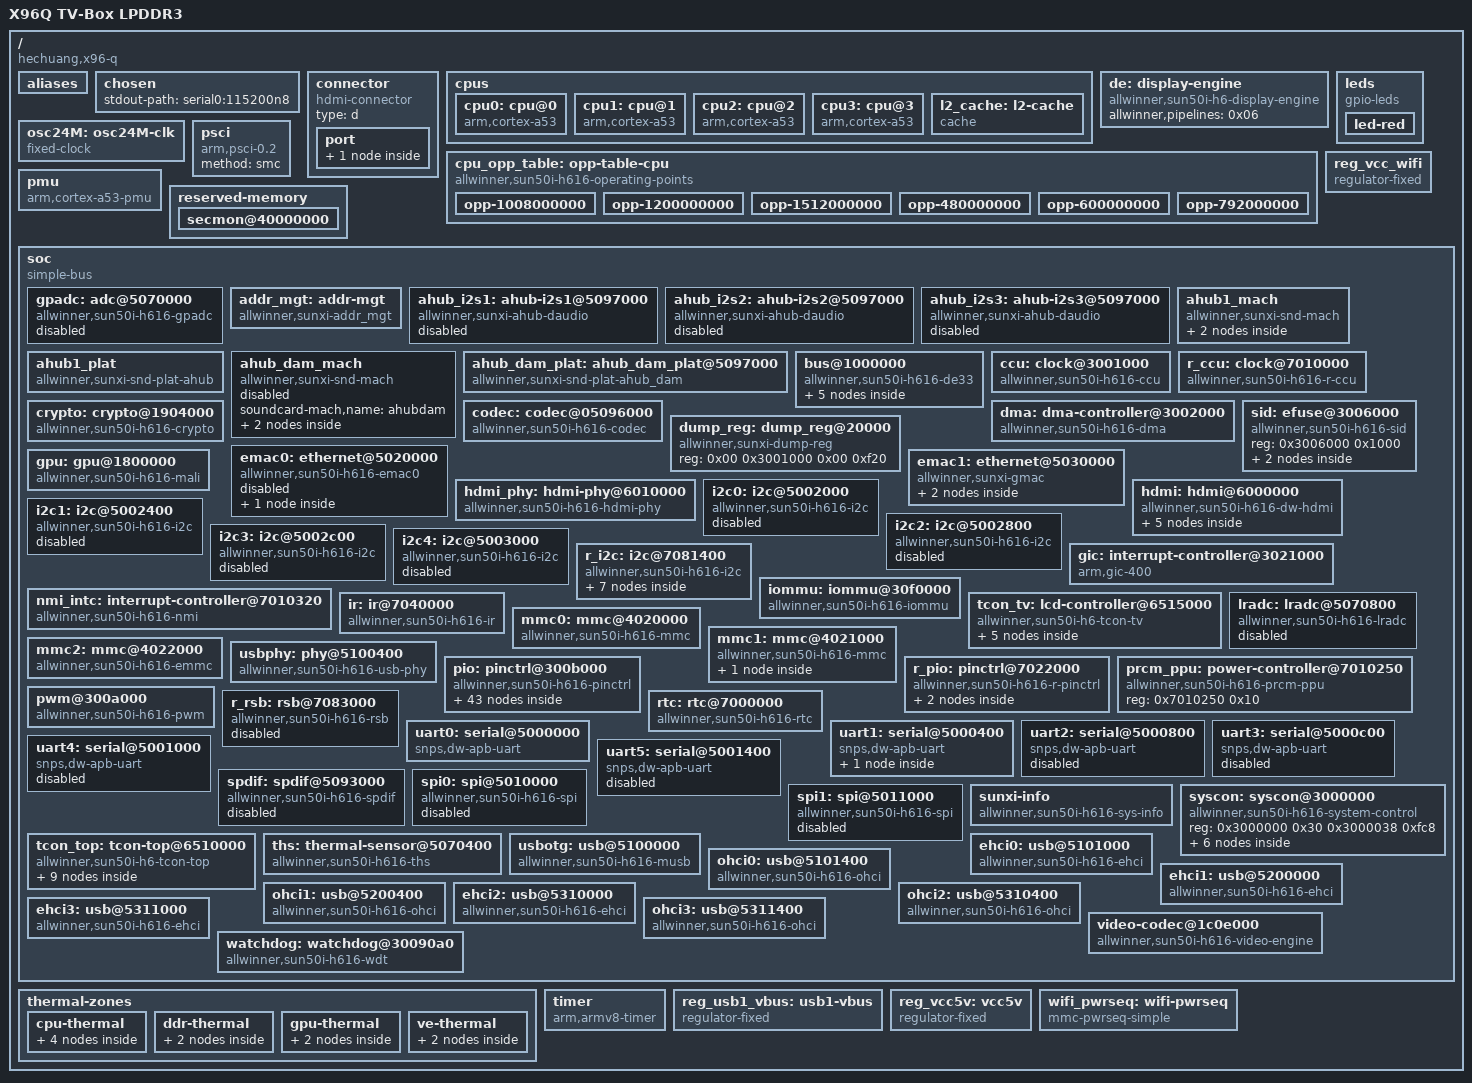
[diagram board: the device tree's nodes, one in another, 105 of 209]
/dts-v1/;

/ {
	#address-cells = <0x02>;
	#size-cells = <0x02>;
	compatible = "hechuang,x96-q", "allwinner,sun50i-h616";
	interrupt-parent = <0x01>;
	model = "X96Q TV-Box LPDDR3";

	__symbols__ {
		addr_mgt = "/soc/addr-mgt";
		ahub1_codec = "/soc/ahub1_mach/soundcard-mach,codec";
		ahub1_cpu = "/soc/ahub1_mach/soundcard-mach,cpu";
		ahub1_mach = "/soc/ahub1_mach";
		ahub1_plat = "/soc/ahub1_plat";
		ahub_dam_mach = "/soc/ahub_dam_mach";
		ahub_dam_plat = "/soc/ahub_dam_plat@5097000";
		ahub_i2s1 = "/soc/ahub-i2s1@5097000";
		ahub_i2s2 = "/soc/ahub-i2s2@5097000";
		ahub_i2s3 = "/soc/ahub-i2s3@5097000";
		axp313a = "/soc/i2c@7081400/pmic@36";
		ccu = "/soc/clock@3001000";
		codec = "/soc/codec@05096000";
		cpu0 = "/cpus/cpu@0";
		cpu1 = "/cpus/cpu@1";
		cpu2 = "/cpus/cpu@2";
		cpu3 = "/cpus/cpu@3";
		cpu_critical = "/thermal-zones/cpu-thermal/trips/cpu-trip-2";
		cpu_opp_table = "/opp-table-cpu";
		cpu_speed_grade = "/soc/efuse@3006000/cpu-speed-grade@0";
		cpu_target = "/thermal-zones/cpu-thermal/trips/cpu-trip-1";
		cpu_threshold = "/thermal-zones/cpu-thermal/trips/cpu-trip-0";
		crypto = "/soc/crypto@1904000";
		ddr_temp_critical = "/thermal-zones/ddr-thermal/trips/ddr-trip-0";
		de = "/display-engine";
		de3_sram = "/soc/syscon@3000000/sram@28000/sram-section@0";
		display_clocks = "/soc/bus@1000000/clock@8000";
		dma = "/soc/dma-controller@3002000";
		dump_reg = "/soc/dump_reg@20000";
		ehci0 = "/soc/usb@5101000";
		ehci1 = "/soc/usb@5200000";
		ehci2 = "/soc/usb@5310000";
		ehci3 = "/soc/usb@5311000";
		emac0 = "/soc/ethernet@5020000";
		emac1 = "/soc/ethernet@5030000";
		ext_rgmii_pins = "/soc/pinctrl@300b000/rgmii-pins";
		gic = "/soc/interrupt-controller@3021000";
		gpadc = "/soc/adc@5070000";
		gpu = "/soc/gpu@1800000";
		gpu_temp_critical = "/thermal-zones/gpu-thermal/trips/gpu-trip-0";
		hdmi = "/soc/hdmi@6000000";
		hdmi_con_in = "/connector/port/endpoint";
		hdmi_in = "/soc/hdmi@6000000/ports/port@0";
		hdmi_in_tcon_top = "/soc/hdmi@6000000/ports/port@0/endpoint";
		hdmi_out = "/soc/hdmi@6000000/ports/port@1";
		hdmi_out_con = "/soc/hdmi@6000000/ports/port@1/endpoint";
		hdmi_phy = "/soc/hdmi-phy@6010000";
		i2c0 = "/soc/i2c@5002000";
		i2c0_pins = "/soc/pinctrl@300b000/i2c0-pins";
		i2c1 = "/soc/i2c@5002400";
		i2c1_pi_pins = "/soc/pinctrl@300b000/i2c1-pi-pins";
		i2c2 = "/soc/i2c@5002800";
		i2c2_ph_pins = "/soc/pinctrl@300b000/i2c2-ph-pins";
		i2c2_pi_pins = "/soc/pinctrl@300b000/i2c2-pi-pins";
		i2c3 = "/soc/i2c@5002c00";
		i2c3_pa_pins = "/soc/pinctrl@300b000/i2c3-pa-pins";
		i2c3_pg_pins = "/soc/pinctrl@300b000/i2c3-pg-pins";
		i2c3_ph_pins = "/soc/pinctrl@300b000/i2c3-ph-pins";
		i2c4 = "/soc/i2c@5003000";
		i2c4_pg_pins = "/soc/pinctrl@300b000/i2c4-pg-pins";
		i2c4_ph_pins = "/soc/pinctrl@300b000/i2c4-ph-pins";
		i2s2_pins = "/soc/pinctrl@300b000/i2s2-pins";
		i2s3_pins = "/soc/pinctrl@300b000/i2s3-pins";
		iommu = "/soc/iommu@30f0000";
		ir = "/soc/ir@7040000";
		ir_rx_pin = "/soc/pinctrl@300b000/ir-rx-pin";
		l2_cache = "/cpus/l2-cache";
		lradc = "/soc/lradc@5070800";
		mdio0 = "/soc/ethernet@5020000/mdio";
		mdio1 = "/soc/ethernet@5030000/mdio";
		mixer0 = "/soc/bus@1000000/mixer@100000";
		mixer0_out = "/soc/bus@1000000/mixer@100000/ports/port@1";
		mixer0_out_tcon_top_mixer0 = "/soc/bus@1000000/mixer@100000/ports/port@1/endpoint";
		mmc0 = "/soc/mmc@4020000";
		mmc0_pins = "/soc/pinctrl@300b000/mmc0-pins";
		mmc1 = "/soc/mmc@4021000";
		mmc1_pins = "/soc/pinctrl@300b000/mmc1-pins";
		mmc2 = "/soc/mmc@4022000";
		mmc2_pins = "/soc/pinctrl@300b000/mmc2-pins";
		nmi_intc = "/soc/interrupt-controller@7010320";
		ohci0 = "/soc/usb@5101400";
		ohci1 = "/soc/usb@5200400";
		ohci2 = "/soc/usb@5310400";
		ohci3 = "/soc/usb@5311400";
		osc24M = "/osc24M-clk";
		pio = "/soc/pinctrl@300b000";
		prcm_ppu = "/soc/power-controller@7010250";
		pwm1_pg_pin = "/soc/pinctrl@300b000/pwm1-pg-pin";
		pwm1_ph_pin = "/soc/pinctrl@300b000/pwm1-ph-pin";
		pwm1_pi_pin = "/soc/pinctrl@300b000/pwm1-pi-pin";
		pwm2_ph_pin = "/soc/pinctrl@300b000/pwm2-ph-pin";
		pwm3_ph_pin = "/soc/pinctrl@300b000/pwm3-ph-pin";
		pwm4_ph_pin = "/soc/pinctrl@300b000/pwm4-ph-pin";
		pwm5_pin = "/soc/pinctrl@300b000/pwm5-pin";
		r_ccu = "/soc/clock@7010000";
		r_i2c = "/soc/i2c@7081400";
		r_i2c_pins = "/soc/pinctrl@7022000/r-i2c-pins";
		r_pio = "/soc/pinctrl@7022000";
		r_rsb = "/soc/rsb@7083000";
		r_rsb_pins = "/soc/pinctrl@7022000/r-rsb-pins";
		reg_aldo1 = "/soc/i2c@7081400/pmic@36/regulators/aldo1";
		reg_dcdc1 = "/soc/i2c@7081400/pmic@36/regulators/dcdc1";
		reg_dcdc2 = "/soc/i2c@7081400/pmic@36/regulators/dcdc2";
		reg_dcdc3 = "/soc/i2c@7081400/pmic@36/regulators/dcdc3";
		reg_dldo1 = "/soc/i2c@7081400/pmic@36/regulators/dldo1";
		reg_usb1_vbus = "/usb1-vbus";
		reg_vcc5v = "/vcc5v";
		reg_vcc_wifi = "/reg_vcc_wifi";
		rmii_phy = "/soc/ethernet@5030000/mdio/ethernet-phy@0";
		rmii_pins = "/soc/pinctrl@300b000/rmii-pins";
		rtc = "/soc/rtc@7000000";
		scpi_sram = "/soc/syscon@3000000/sram@100000/scpi-sram@17c00";
		sid = "/soc/efuse@3006000";
		spdif = "/soc/spdif@5093000";
		spdif_tx_pin = "/soc/pinctrl@300b000/spdif-tx-pin";
		spi0 = "/soc/spi@5010000";
		spi0_cs0_pin = "/soc/pinctrl@300b000/spi0-cs0-pin";
		spi0_pins = "/soc/pinctrl@300b000/spi0-pins";
		spi1 = "/soc/spi@5011000";
		spi1_cs0_pin = "/soc/pinctrl@300b000/spi1-cs0-pin";
		spi1_cs1_pin = "/soc/pinctrl@300b000/spi1-cs1-pin";
		spi1_pins = "/soc/pinctrl@300b000/spi1-pins";
		sram_a2 = "/soc/syscon@3000000/sram@100000";
		sram_c = "/soc/syscon@3000000/sram@28000";
		sram_c1 = "/soc/syscon@3000000/sram@1a00000";
		syscon = "/soc/syscon@3000000";
		tcon_top = "/soc/tcon-top@6510000";
		tcon_top_hdmi_in = "/soc/tcon-top@6510000/ports/port@4";
		tcon_top_hdmi_in_tcon_tv = "/soc/tcon-top@6510000/ports/port@4/endpoint@0";
		tcon_top_hdmi_out = "/soc/tcon-top@6510000/ports/port@5";
		tcon_top_hdmi_out_hdmi = "/soc/tcon-top@6510000/ports/port@5/endpoint";
		tcon_top_mixer0_in = "/soc/tcon-top@6510000/ports/port@0";
		tcon_top_mixer0_in_mixer0 = "/soc/tcon-top@6510000/ports/port@0/endpoint@0";
		tcon_top_mixer0_out = "/soc/tcon-top@6510000/ports/port@1";
		tcon_top_mixer0_out_tcon_tv = "/soc/tcon-top@6510000/ports/port@1/endpoint@2";
		tcon_tv = "/soc/lcd-controller@6515000";
		tcon_tv_in = "/soc/lcd-controller@6515000/ports/port@0";
		tcon_tv_in_tcon_top_mixer0 = "/soc/lcd-controller@6515000/ports/port@0/endpoint";
		tcon_tv_out = "/soc/lcd-controller@6515000/ports/port@1";
		tcon_tv_out_tcon_top = "/soc/lcd-controller@6515000/ports/port@1/endpoint@1";
		ths = "/soc/thermal-sensor@5070400";
		ths_calibration = "/soc/efuse@3006000/thermal-sensor-calibration@14";
		uart0 = "/soc/serial@5000000";
		uart0_ph_pins = "/soc/pinctrl@300b000/uart0-ph-pins";
		uart1 = "/soc/serial@5000400";
		uart1_pins = "/soc/pinctrl@300b000/uart1-pins";
		uart1_rts_cts_pins = "/soc/pinctrl@300b000/uart1-rts-cts-pins";
		uart2 = "/soc/serial@5000800";
		uart2_pg_pins = "/soc/pinctrl@300b000/uart2-pg-pins";
		uart2_pg_rts_cts_pins = "/soc/pinctrl@300b000/uart2-pg-rts-cts-pins";
		uart2_ph_pins = "/soc/pinctrl@300b000/uart2-ph-pins";
		uart2_ph_rts_cts_pins = "/soc/pinctrl@300b000/uart2-ph-rts-cts-pins";
		uart2_pi_pins = "/soc/pinctrl@300b000/uart2-pi-pins";
		uart3 = "/soc/serial@5000c00";
		uart3_pi_pins = "/soc/pinctrl@300b000/uart3-pi-pins";
		uart4 = "/soc/serial@5001000";
		uart4_pi_pins = "/soc/pinctrl@300b000/uart4-pi-pins";
		uart4_pi_rts_cts_pins = "/soc/pinctrl@300b000/uart4-pi-rts-cts-pins";
		uart5 = "/soc/serial@5001400";
		uart5_pins = "/soc/pinctrl@300b000/uart5-pins";
		usbotg = "/soc/usb@5100000";
		usbphy = "/soc/phy@5100400";
		ve_sram = "/soc/syscon@3000000/sram@1a00000/sram-section@0";
		ve_temp_critical = "/thermal-zones/ve-thermal/trips/ve-trip-0";
		watchdog = "/soc/watchdog@30090a0";
		wifi_pwrseq = "/wifi-pwrseq";
		wlan = "/soc/mmc@4021000/wifi@1";
		x32clk_fanout_pin = "/soc/pinctrl@300b000/x32clk-fanout-pin";
	};

	aliases {
		ethernet0 = "/soc/ethernet@5030000";
		ethernet1 = "/soc/mmc@4021000/wifi@1";
		mmc0 = "/soc/mmc@4020000";
		mmc2 = "/soc/mmc@4022000";
		serial0 = "/soc/serial@5000000";
	};

	chosen {
		stdout-path = "serial0:115200n8";
	};

	connector {
		compatible = "hdmi-connector";
		type = "d";

		port {

			hdmi_con_in: endpoint {
				phandle = <0x2e>;
				remote-endpoint = <0x3d>;
			};
		};
	};

	cpus {
		#address-cells = <0x01>;
		#size-cells = <0x00>;

		cpu0: cpu@0 {
			#cooling-cells = <0x02>;
			clocks = <0x02 0x15>;
			compatible = "arm,cortex-a53";
			cpu-supply = <0x05>;
			d-cache-line-size = <0x40>;
			d-cache-sets = <0x80>;
			d-cache-size = <0x8000>;
			device_type = "cpu";
			enable-method = "psci";
			i-cache-line-size = <0x40>;
			i-cache-sets = <0x100>;
			i-cache-size = <0x8000>;
			next-level-cache = <0x03>;
			operating-points-v2 = <0x04>;
			phandle = <0x07>;
			reg = <0x00>;
			status = "okay";
		};

		cpu1: cpu@1 {
			#cooling-cells = <0x02>;
			clocks = <0x02 0x15>;
			compatible = "arm,cortex-a53";
			d-cache-line-size = <0x40>;
			d-cache-sets = <0x80>;
			d-cache-size = <0x8000>;
			device_type = "cpu";
			enable-method = "psci";
			i-cache-line-size = <0x40>;
			i-cache-sets = <0x100>;
			i-cache-size = <0x8000>;
			next-level-cache = <0x03>;
			operating-points-v2 = <0x04>;
			phandle = <0x08>;
			reg = <0x01>;
		};

		cpu2: cpu@2 {
			#cooling-cells = <0x02>;
			clocks = <0x02 0x15>;
			compatible = "arm,cortex-a53";
			d-cache-line-size = <0x40>;
			d-cache-sets = <0x80>;
			d-cache-size = <0x8000>;
			device_type = "cpu";
			enable-method = "psci";
			i-cache-line-size = <0x40>;
			i-cache-sets = <0x100>;
			i-cache-size = <0x8000>;
			next-level-cache = <0x03>;
			operating-points-v2 = <0x04>;
			phandle = <0x09>;
			reg = <0x02>;
		};

		cpu3: cpu@3 {
			#cooling-cells = <0x02>;
			clocks = <0x02 0x15>;
			compatible = "arm,cortex-a53";
			d-cache-line-size = <0x40>;
			d-cache-sets = <0x80>;
			d-cache-size = <0x8000>;
			device_type = "cpu";
			enable-method = "psci";
			i-cache-line-size = <0x40>;
			i-cache-sets = <0x100>;
			i-cache-size = <0x8000>;
			next-level-cache = <0x03>;
			operating-points-v2 = <0x04>;
			phandle = <0x0a>;
			reg = <0x03>;
		};

		l2_cache: l2-cache {
			cache-level = <0x02>;
			cache-line-size = <0x40>;
			cache-sets = <0x100>;
			cache-size = <0x40000>;
			cache-unified;
			compatible = "cache";
			phandle = <0x03>;
		};
	};

	de: display-engine {
		allwinner,pipelines = <0x06>;
		compatible = "allwinner,sun50i-h6-display-engine";
		phandle = <0x3e>;
		status = "okay";
	};

	leds {
		compatible = "gpio-leds";

		led-red {
			color = <0x01>;
			function = "disk-activity";
			gpios = <0x18 0x07 0x06 0x00>;
			linux,default-trigger = "mmc0";
		};
	};

	cpu_opp_table: opp-table-cpu {
		compatible = "allwinner,sun50i-h616-operating-points";
		nvmem-cells = <0x3c>;
		opp-shared;
		phandle = <0x04>;

		opp-1008000000 {
			clock-latency-ns = <0x3b9b0>;
			opp-hz = <0x00 0x3c14dc00>;
			opp-microvolt-speed0 = <0xe09c0 0xe09c0 0x10c8e0>;
			opp-microvolt-speed1 = <0xe09c0 0xe09c0 0x10c8e0>;
			opp-microvolt-speed2 = <0xe09c0 0xe09c0 0x10c8e0>;
		};

		opp-1200000000 {
			clock-latency-ns = <0x3b9b0>;
			opp-hz = <0x00 0x47868c00>;
			opp-microvolt-speed0 = <0xef420 0xef420 0x10c8e0>;
			opp-microvolt-speed1 = <0xef420 0xef420 0x10c8e0>;
			opp-microvolt-speed2 = <0xef420 0xef420 0x10c8e0>;
		};

		opp-1512000000 {
			clock-latency-ns = <0x3b9b0>;
			opp-hz = <0x00 0x5a1f4a00>;
			opp-microvolt-speed0 = <0x10c8e0 0x10c8e0 0x10c8e0>;
			opp-microvolt-speed1 = <0x10c8e0 0x10c8e0 0x10c8e0>;
			opp-microvolt-speed2 = <0x10c8e0 0x10c8e0 0x10c8e0>;
		};

		opp-480000000 {
			clock-latency-ns = <0x3b9b0>;
			opp-hz = <0x00 0x1c9c3800>;
			opp-microvolt-speed0 = <0xdbba0 0xdbba0 0x10c8e0>;
			opp-microvolt-speed1 = <0xdbba0 0xdbba0 0x10c8e0>;
			opp-microvolt-speed2 = <0xdbba0 0xdbba0 0x10c8e0>;
		};

		opp-600000000 {
			clock-latency-ns = <0x3b9b0>;
			opp-hz = <0x00 0x23c34600>;
			opp-microvolt-speed0 = <0xdbba0 0xdbba0 0x10c8e0>;
			opp-microvolt-speed1 = <0xdbba0 0xdbba0 0x10c8e0>;
			opp-microvolt-speed2 = <0xdbba0 0xdbba0 0x10c8e0>;
		};

		opp-792000000 {
			clock-latency-ns = <0x3b9b0>;
			opp-hz = <0x00 0x2f34f600>;
			opp-microvolt-speed0 = <0xdbba0 0xdbba0 0x10c8e0>;
			opp-microvolt-speed1 = <0xdbba0 0xdbba0 0x10c8e0>;
			opp-microvolt-speed2 = <0xdbba0 0xdbba0 0x10c8e0>;
		};
	};

	osc24M: osc24M-clk {
		#clock-cells = <0x00>;
		clock-frequency = <0x16e3600>;
		clock-output-names = "osc24M";
		compatible = "fixed-clock";
		phandle = <0x12>;
	};

	pmu {
		compatible = "arm,cortex-a53-pmu";
		interrupt-affinity = <0x07 0x08 0x09 0x0a>;
		interrupts = <0x00 0x8c 0x04 0x00 0x8d 0x04 0x00 0x8e 0x04 0x00 0x8f 0x04>;
	};

	psci {
		compatible = "arm,psci-0.2";
		method = "smc";
	};

	reg_vcc_wifi: reg_vcc_wifi {
		compatible = "regulator-fixed";
		enable-active-high;
		gpio = <0x18 0x06 0x12 0x00>;
		phandle = <0x16>;
		regulator-always-on;
		regulator-max-microvolt = <0x325aa0>;
		regulator-min-microvolt = <0x325aa0>;
		regulator-name = "vcc-wifi";
		status = "okay";
	};

	reserved-memory {
		#address-cells = <0x02>;
		#size-cells = <0x02>;
		ranges;

		secmon@40000000 {
			no-map;
			reg = <0x00 0x40000000 0x00 0x80000>;
		};
	};

	soc {
		#address-cells = <0x01>;
		#size-cells = <0x01>;
		compatible = "simple-bus";
		ranges = <0x00 0x00 0x00 0x40000000>;

		gpadc: adc@5070000 {
			#io-channel-cells = <0x01>;
			clocks = <0x02 0x81>;
			compatible = "allwinner,sun50i-h616-gpadc", "allwinner,sun20i-d1-gpadc";
			interrupts = <0x00 0x12 0x04>;
			phandle = <0x80>;
			reg = <0x5070000 0x400>;
			resets = <0x02 0x3c>;
			status = "disabled";
		};

		addr_mgt: addr-mgt {
			compatible = "allwinner,sunxi-addr_mgt";
			phandle = <0xa2>;
			status = "okay";
			type_addr_bt = <0x02>;
			type_addr_eth = <0x02>;
			type_addr_wifi = <0x02>;
		};

		ahub_i2s1: ahub-i2s1@5097000 {
			#sound-dai-cells = <0x00>;
			audio_format = <0x01>;
			clock-names = "apb", "audio-codec-1x", "audio-codec-4x", "audio-hub";
			clocks = <0x02 0x5f 0x02 0x5b 0x02 0x5c 0x02 0x5e>;
			compatible = "allwinner,sunxi-ahub-daudio";
			daudio_master = <0x04>;
			frametype = <0x00>;
			mclk_div = <0x01>;
			pcm_lrck_period = <0x20>;
			phandle = <0x86>;
			pinconfig = <0x00>;
			reg = <0x5097000 0xadf>;
			signal_inversion = <0x01>;
			slot_width_select = <0x20>;
			status = "disabled";
			tdm_config = <0x01>;
			tdm_num = <0x01>;
		};

		ahub_i2s2: ahub-i2s2@5097000 {
			audio_format = <0x01>;
			clock-names = "apb", "audio-codec-1x", "audio-codec-4x", "audio-hub";
			clocks = <0x02 0x5f 0x02 0x5b 0x02 0x5c 0x02 0x5e>;
			compatible = "allwinner,sunxi-ahub-daudio";
			daudio_master = <0x04>;
			frametype = <0x00>;
			mclk_div = <0x04>;
			pcm_lrck_period = <0x20>;
			phandle = <0x87>;
			pinconfig = <0x01>;
			reg = <0x5097000 0xadf>;
			signal_inversion = <0x01>;
			slot_width_select = <0x20>;
			status = "disabled";
			tdm_config = <0x01>;
			tdm_num = <0x02>;
		};

		ahub_i2s3: ahub-i2s3@5097000 {
			audio_format = <0x01>;
			clock-names = "apb", "audio-codec-1x", "audio-codec-4x", "audio-hub";
			clocks = <0x02 0x5f 0x02 0x5b 0x02 0x5c 0x02 0x5e>;
			compatible = "allwinner,sunxi-ahub-daudio";
			daudio_master = <0x04>;
			frametype = <0x00>;
			mclk_div = <0x04>;
			pcm_lrck_period = <0x20>;
			phandle = <0x88>;
			pinconfig = <0x01>;
			reg = <0x5097000 0xadf>;
			signal_inversion = <0x01>;
			slot_width_select = <0x20>;
			status = "disabled";
			tdm_config = <0x01>;
			tdm_num = <0x03>;
		};

		ahub1_mach: ahub1_mach {
			compatible = "allwinner,sunxi-snd-mach";
			phandle = <0x84>;
			soundcard-mach,bitclock-master = <0x27>;
			soundcard-mach,format = "i2s";
			soundcard-mach,frame-master = <0x27>;
			soundcard-mach,name = "HDMI";
			soundcard-mach,slot-num = <0x02>;
			soundcard-mach,slot-width = <0x20>;
			status = "okay";

			ahub1_codec: soundcard-mach,codec {
				phandle = <0x85>;
				sound-dai = <0x29>;
			};

			ahub1_cpu: soundcard-mach,cpu {
				phandle = <0x27>;
				sound-dai = <0x28>;
				soundcard-mach,mclk-fs = <0x00>;
				soundcard-mach,pll-fs = <0x04>;
			};
		};

		ahub1_plat: ahub1_plat {
			#sound-dai-cells = <0x00>;
			apb_num = <0x01>;
			capture_cma = <0x80>;
			compatible = "allwinner,sunxi-snd-plat-ahub";
			dma-names = "tx", "rx";
			dmas = <0x1a 0x04 0x1a 0x04>;
			phandle = <0x28>;
			playback_cma = <0x80>;
			rx_fifo_size = <0x80>;
			rx_pin = <0x00>;
			status = "okay";
			tdm_num = <0x01>;
			tx_fifo_size = <0x80>;
			tx_pin = <0x00>;
		};

		ahub_dam_mach: ahub_dam_mach {
			compatible = "allwinner,sunxi-snd-mach";
			phandle = <0x83>;
			soundcard-mach,name = "ahubdam";
			status = "disabled";

			soundcard-mach,codec {
			};

			soundcard-mach,cpu {
				sound-dai = <0x26>;
			};
		};

		ahub_dam_plat: ahub_dam_plat@5097000 {
			#sound-dai-cells = <0x00>;
			clock-names = "clk_pll_audio", "clk_pll_audio_4x", "clk_audio_hub", "clk_bus_audio_hub";
			clocks = <0x02 0x5b 0x02 0x5c 0x02 0x5e 0x02 0x5f>;
			compatible = "allwinner,sunxi-snd-plat-ahub_dam";
			phandle = <0x26>;
			reg = <0x5097000 0x1000>;
			resets = <0x02 0x25>;
			status = "okay";
		};

		bus@1000000 {
			#address-cells = <0x01>;
			#size-cells = <0x01>;
			allwinner,sram = <0x0b 0x01>;
			compatible = "allwinner,sun50i-h616-de33", "allwinner,sun50i-a64-de2";
			ranges = <0x00 0x1000000 0x400000>;
			reg = <0x1000000 0x400000>;

			display_clocks: clock@8000 {
				#clock-cells = <0x01>;
				#reset-cells = <0x01>;
				clock-names = "mod", "bus";
				clocks = <0x02 0x1d 0x02 0x1e>;
				compatible = "allwinner,sun50i-h616-de33-clk";
				phandle = <0x0c>;
				reg = <0x8000 0x100>;
				resets = <0x02 0x01>;
			};

			mixer0: mixer@100000 {
				clock-names = "bus", "mod";
				clocks = <0x0c 0x00 0x0c 0x06>;
				compatible = "allwinner,sun50i-h616-de33-mixer-0";
				phandle = <0x06>;
				reg = <0x100000 0x100000 0x8100 0x40 0x280000 0x20000>;
				resets = <0x0c 0x00>;

				ports {
					#address-cells = <0x01>;
					#size-cells = <0x00>;

					mixer0_out: port@1 {
						phandle = <0x3f>;
						reg = <0x01>;

						mixer0_out_tcon_top_mixer0: endpoint {
							phandle = <0x2f>;
							remote-endpoint = <0x0d>;
						};
					};
				};
			};
		};

		ccu: clock@3001000 {
			#clock-cells = <0x01>;
			#reset-cells = <0x01>;
			clock-names = "hosc", "losc", "iosc";
			clocks = <0x12 0x10 0x00 0x10 0x02>;
			compatible = "allwinner,sun50i-h616-ccu";
			phandle = <0x02>;
			reg = <0x3001000 0x1000>;
		};

		r_ccu: clock@7010000 {
			#clock-cells = <0x01>;
			#reset-cells = <0x01>;
			clock-names = "hosc", "losc", "iosc", "pll-periph";
			clocks = <0x12 0x10 0x00 0x10 0x02 0x02 0x04>;
			compatible = "allwinner,sun50i-h616-r-ccu";
			phandle = <0x36>;
			reg = <0x7010000 0x210>;
		};

		codec: codec@05096000 {
			#sound-dai-cells = <0x00>;
			allwinner,audio-routing = "Line Out", "LINEOUT";
			clock-names = "apb", "audio-codec-1x", "audio-codec-4x";
			clocks = <0x02 0x5d 0x02 0x5b 0x02 0x5c>;
			compatible = "allwinner,sun50i-h616-codec";
			dma-names = "tx";
			dmas = <0x1a 0x06>;
			interrupts = <0x00 0x3a 0x04>;
			phandle = <0x82>;
			reg = <0x5096000 0x31c>;
			resets = <0x02 0x24>;
			status = "okay";
		};

		crypto: crypto@1904000 {
			clock-names = "bus", "mod", "ram", "trng";
			clocks = <0x02 0x27 0x02 0x26 0x02 0x34 0x10 0x02>;
			compatible = "allwinner,sun50i-h616-crypto";
			interrupts = <0x00 0x5b 0x04>;
			phandle = <0x41>;
			reg = <0x1904000 0x800>;
			resets = <0x02 0x04>;
		};

		dma: dma-controller@3002000 {
			#dma-cells = <0x01>;
			clock-names = "bus", "mbus";
			clocks = <0x02 0x2a 0x02 0x32>;
			compatible = "allwinner,sun50i-h616-dma", "allwinner,sun50i-a100-dma";
			dma-channels = <0x10>;
			dma-requests = <0x31>;
			interrupts = <0x00 0x2a 0x04>;
			phandle = <0x1a>;
			reg = <0x3002000 0x1000>;
			resets = <0x02 0x06>;
		};

		dump_reg: dump_reg@20000 {
			compatible = "allwinner,sunxi-dump-reg";
			phandle = <0xa1>;
			reg = <0x00 0x3001000 0x00 0xf20>;
			status = "okay";
		};

		sid: efuse@3006000 {
			#address-cells = <0x01>;
			#size-cells = <0x01>;
			compatible = "allwinner,sun50i-h616-sid", "allwinner,sun50i-a64-sid";
			phandle = <0x46>;
			reg = <0x3006000 0x1000>;

			cpu_speed_grade: cpu-speed-grade@0 {
				phandle = <0x3c>;
				reg = <0x00 0x02>;
			};

			ths_calibration: thermal-sensor-calibration@14 {
				phandle = <0x25>;
				reg = <0x14 0x08>;
			};
		};

		emac0: ethernet@5020000 {
			clock-names = "stmmaceth";
			clocks = <0x02 0x52>;
			compatible = "allwinner,sun50i-h616-emac0", "allwinner,sun50i-a64-emac";
			interrupt-names = "macirq";
			interrupts = <0x00 0x0e 0x04>;
			phandle = <0x7b>;
			reg = <0x5020000 0x10000>;
			reset-names = "stmmaceth";
			resets = <0x02 0x1e>;
			status = "disabled";
			syscon = <0x20>;

			mdio0: mdio {
				#address-cells = <0x01>;
				#size-cells = <0x00>;
				compatible = "snps,dwmac-mdio";
				phandle = <0x7c>;
			};
		};

		emac1: ethernet@5030000 {
			allwinner,rx-delay-ps = <0xc1c>;
			allwinner,tx-delay-ps = <0x2bc>;
			clock-names = "bus-emac1", "emac-25m";
			clocks = <0x02 0x53 0x02 0x51>;
			compatible = "allwinner,sunxi-gmac";
			gmac-power0;
			gmac-power1;
			gmac-power2;
			interrupt-names = "gmacirq";
			interrupts = <0x00 0x0f 0x04>;
			phandle = <0x7d>;
			phy-handle = <0x22>;
			phy-mode = "rmii";
			phy-rst;
			phy-supply = <0x23>;
			pinctrl-0 = <0x21>;
			pinctrl-names = "default";
			reg = <0x5030000 0x10000 0x3000034 0x04>;
			reg-names = "gmac1_reg", "ephy_reg";
			reset-names = "stmmaceth";
			resets = <0x02 0x1f>;
			rx-delay = <0x1f>;
			status = "okay";
			tx-delay = <0x07>;

			mdio1: mdio {
				#address-cells = <0x01>;
				#size-cells = <0x00>;
				compatible = "ethernet-phy-ieee802.3-c22";
				phandle = <0x7e>;

				rmii_phy: ethernet-phy@0 {
					compatible = "ethernet-phy-ieee802.3-c22";
					phandle = <0x22>;
					reg = <0x00>;
				};
			};
		};

		gpu: gpu@1800000 {
			clock-names = "core", "bus";
			clocks = <0x02 0x23 0x02 0x24>;
			compatible = "allwinner,sun50i-h616-mali", "arm,mali-bifrost";
			interrupt-names = "job", "mmu", "gpu";
			interrupts = <0x00 0x5f 0x04 0x00 0x60 0x04 0x00 0x61 0x04>;
			mali-supply = <0x0f>;
			phandle = <0x40>;
			power-domains = <0x0e 0x02>;
			reg = <0x1800000 0x40000>;
			resets = <0x02 0x03>;
			status = "okay";
		};

		hdmi_phy: hdmi-phy@6010000 {
			#phy-cells = <0x00>;
			clock-names = "bus", "mod";
			clocks = <0x02 0x75 0x02 0x73>;
			compatible = "allwinner,sun50i-h616-hdmi-phy";
			phandle = <0x2c>;
			reg = <0x6010000 0x10000>;
			reset-names = "phy";
			resets = <0x02 0x34>;
		};

		hdmi: hdmi@6000000 {
			#sound-dai-cells = <0x00>;
			clock-names = "iahb", "isfr", "tmds", "cec", "hdcp", "hdcp-bus";
			clocks = <0x02 0x75 0x02 0x73 0x02 0x72 0x02 0x74 0x02 0x7e 0x02 0x7f>;
			compatible = "allwinner,sun50i-h616-dw-hdmi", "allwinner,sun50i-h6-dw-hdmi";
			hvcc-supply = <0x23>;
			interrupts = <0x00 0x3f 0x04>;
			phandle = <0x29>;
			phy-names = "phy";
			phys = <0x2c>;
			reg = <0x6000000 0x10000>;
			reg-io-width = <0x01>;
			reset-names = "ctrl", "hdcp";
			resets = <0x02 0x33 0x02 0x3a>;
			status = "okay";

			ports {
				#address-cells = <0x01>;
				#size-cells = <0x00>;

				hdmi_in: port@0 {
					phandle = <0x92>;
					reg = <0x00>;

					hdmi_in_tcon_top: endpoint {
						phandle = <0x32>;
						remote-endpoint = <0x2d>;
					};
				};

				hdmi_out: port@1 {
					phandle = <0x93>;
					reg = <0x01>;

					hdmi_out_con: endpoint {
						phandle = <0x3d>;
						remote-endpoint = <0x2e>;
					};
				};
			};
		};

		i2c0: i2c@5002000 {
			#address-cells = <0x01>;
			#size-cells = <0x00>;
			clocks = <0x02 0x48>;
			compatible = "allwinner,sun50i-h616-i2c", "allwinner,sun8i-v536-i2c", "allwinner,sun6i-a31-i2c";
			dma-names = "rx", "tx";
			dmas = <0x1a 0x2b 0x1a 0x2b>;
			interrupts = <0x00 0x06 0x04>;
			phandle = <0x74>;
			pinctrl-0 = <0x1f>;
			pinctrl-names = "default";
			reg = <0x5002000 0x400>;
			resets = <0x02 0x17>;
			status = "disabled";
		};

		i2c1: i2c@5002400 {
			#address-cells = <0x01>;
			#size-cells = <0x00>;
			clocks = <0x02 0x49>;
			compatible = "allwinner,sun50i-h616-i2c", "allwinner,sun8i-v536-i2c", "allwinner,sun6i-a31-i2c";
			dma-names = "rx", "tx";
			dmas = <0x1a 0x2c 0x1a 0x2c>;
			interrupts = <0x00 0x07 0x04>;
			phandle = <0x75>;
			reg = <0x5002400 0x400>;
			resets = <0x02 0x18>;
			status = "disabled";
		};

		i2c2: i2c@5002800 {
			#address-cells = <0x01>;
			#size-cells = <0x00>;
			clocks = <0x02 0x4a>;
			compatible = "allwinner,sun50i-h616-i2c", "allwinner,sun8i-v536-i2c", "allwinner,sun6i-a31-i2c";
			dma-names = "rx", "tx";
			dmas = <0x1a 0x2d 0x1a 0x2d>;
			interrupts = <0x00 0x08 0x04>;
			phandle = <0x76>;
			reg = <0x5002800 0x400>;
			resets = <0x02 0x19>;
			status = "disabled";
		};

		i2c3: i2c@5002c00 {
			#address-cells = <0x01>;
			#size-cells = <0x00>;
			clocks = <0x02 0x4b>;
			compatible = "allwinner,sun50i-h616-i2c", "allwinner,sun8i-v536-i2c", "allwinner,sun6i-a31-i2c";
			dma-names = "rx", "tx";
			dmas = <0x1a 0x2e 0x1a 0x2e>;
			interrupts = <0x00 0x09 0x04>;
			phandle = <0x77>;
			reg = <0x5002c00 0x400>;
			resets = <0x02 0x1a>;
			status = "disabled";
		};

		i2c4: i2c@5003000 {
			#address-cells = <0x01>;
			#size-cells = <0x00>;
			clocks = <0x02 0x4c>;
			compatible = "allwinner,sun50i-h616-i2c", "allwinner,sun8i-v536-i2c", "allwinner,sun6i-a31-i2c";
			dma-names = "rx", "tx";
			dmas = <0x1a 0x2f 0x1a 0x2f>;
			interrupts = <0x00 0x0a 0x04>;
			phandle = <0x78>;
			reg = <0x5003000 0x400>;
			resets = <0x02 0x1b>;
			status = "disabled";
		};

		r_i2c: i2c@7081400 {
			#address-cells = <0x01>;
			#size-cells = <0x00>;
			clocks = <0x36 0x08>;
			compatible = "allwinner,sun50i-h616-i2c", "allwinner,sun8i-v536-i2c", "allwinner,sun6i-a31-i2c";
			dma-names = "rx", "tx";
			dmas = <0x1a 0x30 0x1a 0x30>;
			interrupts = <0x00 0x69 0x04>;
			phandle = <0x9d>;
			pinctrl-0 = <0x38>;
			pinctrl-names = "default";
			reg = <0x7081400 0x400>;
			resets = <0x36 0x04>;
			status = "okay";

			axp313a: pmic@36 {
				compatible = "x-powers,axp313a";
				phandle = <0x9e>;
				reg = <0x36>;
				vin1-supply = <0x39>;
				vin2-supply = <0x39>;
				vin3-supply = <0x39>;
				wakeup-source;

				regulators {

					reg_aldo1: aldo1 {
						phandle = <0x23>;
						regulator-always-on;
						regulator-max-microvolt = <0x1b7740>;
						regulator-min-microvolt = <0x1b7740>;
						regulator-name = "vcc1v8";
					};

					reg_dcdc1: dcdc1 {
						phandle = <0x0f>;
						regulator-always-on;
						regulator-max-microvolt = <0x11b340>;
						regulator-min-microvolt = <0xc5c10>;
						regulator-name = "vdd-gpu";
					};

					reg_dcdc2: dcdc2 {
						phandle = <0x05>;
						regulator-always-on;
						regulator-max-microvolt = <0x11b340>;
						regulator-min-microvolt = <0xc5c10>;
						regulator-name = "vdd-cpu";
					};

					reg_dcdc3: dcdc3 {
						phandle = <0x9f>;
						regulator-always-on;
						regulator-max-microvolt = <0x124f80>;
						regulator-min-microvolt = <0x124f80>;
						regulator-name = "vdd-dram";
					};

					reg_dldo1: dldo1 {
						phandle = <0x14>;
						regulator-always-on;
						regulator-max-microvolt = <0x325aa0>;
						regulator-min-microvolt = <0x325aa0>;
						regulator-name = "vcc3v3";
					};
				};
			};
		};

		gic: interrupt-controller@3021000 {
			#interrupt-cells = <0x03>;
			compatible = "arm,gic-400";
			interrupt-controller;
			interrupts = <0x01 0x09 0xf04>;
			phandle = <0x01>;
			reg = <0x3021000 0x1000 0x3022000 0x2000 0x3024000 0x2000 0x3026000 0x2000>;
		};

		nmi_intc: interrupt-controller@7010320 {
			#interrupt-cells = <0x02>;
			compatible = "allwinner,sun50i-h616-nmi", "allwinner,sun9i-a80-nmi";
			interrupt-controller;
			interrupts = <0x00 0x67 0x04>;
			phandle = <0x9b>;
			reg = <0x7010320 0x0c>;
		};

		iommu: iommu@30f0000 {
			#iommu-cells = <0x01>;
			clocks = <0x02 0x30>;
			compatible = "allwinner,sun50i-h616-iommu", "allwinner,sun50i-h6-iommu";
			interrupts = <0x00 0x3d 0x04>;
			phandle = <0x69>;
			reg = <0x30f0000 0x10000>;
			resets = <0x02 0x0b>;
		};

		ir: ir@7040000 {
			clock-names = "apb", "ir";
			clocks = <0x36 0x09 0x36 0x0b>;
			compatible = "allwinner,sun50i-h616-ir", "allwinner,sun6i-a31-ir";
			interrupts = <0x00 0x6a 0x04>;
			linux,rc-map-name = "rc-beelink-gs1";
			phandle = <0x9c>;
			pinctrl-0 = <0x37>;
			pinctrl-names = "default";
			reg = <0x7040000 0x400>;
			resets = <0x36 0x05>;
			status = "okay";
		};

		tcon_tv: lcd-controller@6515000 {
			clock-names = "ahb", "tcon-ch1";
			clocks = <0x02 0x79 0x33 0x00>;
			compatible = "allwinner,sun50i-h6-tcon-tv", "allwinner,sun8i-r40-tcon-tv";
			interrupts = <0x00 0x42 0x04>;
			phandle = <0x98>;
			reg = <0x6515000 0x1000>;
			reset-names = "lcd";
			resets = <0x02 0x36>;

			ports {
				#address-cells = <0x01>;
				#size-cells = <0x00>;

				tcon_tv_in: port@0 {
					phandle = <0x99>;
					reg = <0x00>;

					tcon_tv_in_tcon_top_mixer0: endpoint {
						phandle = <0x30>;
						remote-endpoint = <0x34>;
					};
				};

				tcon_tv_out: port@1 {
					#address-cells = <0x01>;
					#size-cells = <0x00>;
					phandle = <0x9a>;
					reg = <0x01>;

					tcon_tv_out_tcon_top: endpoint@1 {
						phandle = <0x31>;
						reg = <0x01>;
						remote-endpoint = <0x35>;
					};
				};
			};
		};

		lradc: lradc@5070800 {
			clocks = <0x02 0x71>;
			compatible = "allwinner,sun50i-h616-lradc", "allwinner,sun50i-r329-lradc";
			interrupts = <0x00 0x14 0x04>;
			phandle = <0x81>;
			reg = <0x5070800 0x400>;
			resets = <0x02 0x3b>;
			status = "disabled";
		};

		mmc0: mmc@4020000 {
			#address-cells = <0x01>;
			#size-cells = <0x00>;
			broken-cd;
			bus-width = <0x04>;
			cap-mmc-highspeed;
			cap-sd-highspeed;
			cap-sdio-irq;
			clock-names = "ahb", "mmc";
			clocks = <0x02 0x3f 0x02 0x3c>;
			compatible = "allwinner,sun50i-h616-mmc", "allwinner,sun50i-a100-mmc";
			interrupts = <0x00 0x23 0x04>;
			max-frequency = <0x8f0d180>;
			mmc-ddr-3_3v;
			phandle = <0x6a>;
			pinctrl-0 = <0x13>;
			pinctrl-names = "default";
			reg = <0x4020000 0x1000>;
			reset-names = "ahb";
			resets = <0x02 0x0e>;
			status = "okay";
			vmmc-supply = <0x14>;
		};

		mmc1: mmc@4021000 {
			#address-cells = <0x01>;
			#size-cells = <0x00>;
			bus-width = <0x04>;
			cap-mmc-highspeed;
			cap-sd-highspeed;
			cap-sdio-irq;
			clock-names = "ahb", "mmc";
			clocks = <0x02 0x40 0x02 0x3d>;
			compatible = "allwinner,sun50i-h616-mmc", "allwinner,sun50i-a100-mmc";
			interrupts = <0x00 0x24 0x04>;
			max-frequency = <0x8f0d180>;
			mmc-ddr-3_3v;
			mmc-pwrseq = <0x17>;
			non-removable;
			phandle = <0x6b>;
			pinctrl-0 = <0x15>;
			pinctrl-names = "default";
			reg = <0x4021000 0x1000>;
			reset-names = "ahb";
			resets = <0x02 0x0f>;
			status = "okay";
			vmmc-supply = <0x14>;
			vqmmc-supply = <0x16>;

			wlan: wifi@1 {
				interrupt-names = "host-wake";
				interrupt-parent = <0x18>;
				interrupts = <0x06 0x0f 0x01>;
				phandle = <0x6c>;
				reg = <0x01>;
			};
		};

		mmc2: mmc@4022000 {
			#address-cells = <0x01>;
			#size-cells = <0x00>;
			bus-width = <0x08>;
			cap-mmc-highspeed;
			cap-mmc-hw-reset;
			cap-sd-highspeed;
			cap-sdio-irq;
			clock-names = "ahb", "mmc";
			clocks = <0x02 0x41 0x02 0x3e>;
			compatible = "allwinner,sun50i-h616-emmc", "allwinner,sun50i-a100-emmc";
			interrupts = <0x00 0x25 0x04>;
			max-frequency = <0x8f0d180>;
			mmc-ddr-3_3v;
			non-removable;
			phandle = <0x6d>;
			pinctrl-0 = <0x19>;
			pinctrl-names = "default";
			reg = <0x4022000 0x1000>;
			reset-names = "ahb";
			resets = <0x02 0x10>;
			status = "okay";
			vmmc-supply = <0x14>;
		};

		usbphy: phy@5100400 {
			#phy-cells = <0x01>;
			clock-names = "usb0_phy", "usb1_phy", "usb2_phy", "usb3_phy", "pmu2_clk";
			clocks = <0x02 0x61 0x02 0x63 0x02 0x65 0x02 0x67 0x02 0x6e>;
			compatible = "allwinner,sun50i-h616-usb-phy";
			phandle = <0x2a>;
			reg = <0x5100400 0x24 0x5101800 0x14 0x5200800 0x14 0x5310800 0x14 0x5311800 0x14>;
			reg-names = "phy_ctrl", "pmu0", "pmu1", "pmu2", "pmu3";
			reset-names = "usb0_reset", "usb1_reset", "usb2_reset", "usb3_reset";
			resets = <0x02 0x26 0x02 0x27 0x02 0x28 0x02 0x29>;
			status = "okay";
			usb1_vbus-supply = <0x2b>;
		};

		pio: pinctrl@300b000 {
			#gpio-cells = <0x03>;
			#interrupt-cells = <0x03>;
			clock-names = "apb", "hosc", "losc";
			clocks = <0x02 0x1a 0x12 0x10 0x00>;
			compatible = "allwinner,sun50i-h616-pinctrl";
			gpio-controller;
			interrupt-controller;
			interrupts = <0x00 0x33 0x04 0x00 0x34 0x04 0x00 0x35 0x04 0x00 0x2b 0x04 0x00 0x36 0x04 0x00 0x37 0x04 0x00 0x38 0x04 0x00 0x39 0x04>;
			phandle = <0x18>;
			reg = <0x300b000 0x400>;

			i2c0_pins: i2c0-pins {
				function = "i2c0";
				phandle = <0x1f>;
				pins = "PI5", "PI6";
			};

			i2c1_pi_pins: i2c1-pi-pins {
				function = "i2c1";
				phandle = <0x49>;
				pins = "PI7", "PI8";
			};

			i2c2_ph_pins: i2c2-ph-pins {
				function = "i2c2";
				phandle = <0x4a>;
				pins = "PH2", "PH3";
			};

			i2c2_pi_pins: i2c2-pi-pins {
				function = "i2c2";
				phandle = <0x4b>;
				pins = "PI9", "PI10";
			};

			i2c3_pa_pins: i2c3-pa-pins {
				bias-pull-up;
				function = "i2c3";
				phandle = <0x4c>;
				pins = "PA10", "PA11";
			};

			i2c3_pg_pins: i2c3-pg-pins {
				function = "i2c3";
				phandle = <0x4d>;
				pins = "PG17", "PG18";
			};

			i2c3_ph_pins: i2c3-ph-pins {
				function = "i2c3";
				phandle = <0x4e>;
				pins = "PH4", "PH5";
			};

			i2c4_pg_pins: i2c4-pg-pins {
				function = "i2c4";
				phandle = <0x4f>;
				pins = "PG15", "PG16";
			};

			i2c4_ph_pins: i2c4-ph-pins {
				function = "i2c4";
				phandle = <0x50>;
				pins = "PH6", "PH7";
			};

			i2s2_pins: i2s2-pins {
				function = "i2s2";
				phandle = <0x51>;
				pins = "PG10", "PG11", "PG12", "PG13", "PG14";
			};

			i2s3_pins: i2s3-pins {
				function = "i2s3";
				phandle = <0x52>;
				pins = "PH5", "PH6", "PH7", "PH8", "PH9";
			};

			ir_rx_pin: ir-rx-pin {
				function = "ir_rx";
				phandle = <0x37>;
				pins = "PH10";
			};

			mmc0_pins: mmc0-pins {
				bias-pull-up;
				drive-strength = <0x1e>;
				function = "mmc0";
				phandle = <0x13>;
				pins = "PF0", "PF1", "PF2", "PF3", "PF4", "PF5";
			};

			mmc1_pins: mmc1-pins {
				bias-pull-up;
				drive-strength = <0x1e>;
				function = "mmc1";
				phandle = <0x15>;
				pins = "PG0", "PG1", "PG2", "PG3", "PG4", "PG5";
			};

			mmc2_pins: mmc2-pins {
				bias-pull-up;
				drive-strength = <0x1e>;
				function = "mmc2";
				phandle = <0x19>;
				pins = "PC0", "PC1", "PC5", "PC6", "PC8", "PC9", "PC10", "PC11", "PC13", "PC14", "PC15", "PC16";
			};

			pwm1_pg_pin: pwm1-pg-pin {
				function = "pwm1";
				phandle = <0x53>;
				pins = "PG19";
			};

			pwm1_ph_pin: pwm1-ph-pin {
				function = "pwm1";
				phandle = <0x54>;
				pins = "PH3";
			};

			pwm1_pi_pin: pwm1-pi-pin {
				function = "pwm1";
				phandle = <0x55>;
				pins = "PI11";
			};

			pwm2_ph_pin: pwm2-ph-pin {
				function = "pwm2";
				phandle = <0x56>;
				pins = "PH2";
			};

			pwm3_ph_pin: pwm3-ph-pin {
				function = "pwm3";
				phandle = <0x57>;
				pins = "PH0";
			};

			pwm4_ph_pin: pwm4-ph-pin {
				function = "pwm4";
				phandle = <0x58>;
				pins = "PH1";
			};

			pwm5_pin: pwm5-pin {
				bias-pull-up;
				function = "pwm5";
				phandle = <0x59>;
				pins = "PA12";
			};

			ext_rgmii_pins: rgmii-pins {
				drive-strength = <0x28>;
				function = "emac0";
				phandle = <0x48>;
				pins = "PI0", "PI1", "PI2", "PI3", "PI4", "PI5", "PI7", "PI8", "PI9", "PI10", "PI11", "PI12", "PI13", "PI14", "PI15";
			};

			rmii_pins: rmii-pins {
				drive-strength = <0x28>;
				function = "emac1";
				phandle = <0x21>;
				pins = "PA0", "PA1", "PA2", "PA3", "PA4", "PA5", "PA6", "PA7", "PA8", "PA9";
			};

			spdif_tx_pin: spdif-tx-pin {
				function = "spdif";
				phandle = <0x24>;
				pins = "PH4";
			};

			spi0_cs0_pin: spi0-cs0-pin {
				function = "spi0";
				phandle = <0x5b>;
				pins = "PC3";
			};

			spi0_pins: spi0-pins {
				function = "spi0";
				phandle = <0x5a>;
				pins = "PC0", "PC2", "PC4";
			};

			spi1_cs0_pin: spi1-cs0-pin {
				function = "spi1";
				phandle = <0x5d>;
				pins = "PH5";
			};

			spi1_cs1_pin: spi1-cs1-pin {
				function = "spi1";
				phandle = <0x5e>;
				pins = "PH9";
			};

			spi1_pins: spi1-pins {
				function = "spi1";
				phandle = <0x5c>;
				pins = "PH6", "PH7", "PH8";
			};

			uart0_ph_pins: uart0-ph-pins {
				function = "uart0";
				phandle = <0x1b>;
				pins = "PH0", "PH1";
			};

			uart1_pins: uart1-pins {
				function = "uart1";
				phandle = <0x1c>;
				pins = "PG6", "PG7";
			};

			uart1_rts_cts_pins: uart1-rts-cts-pins {
				function = "uart1";
				phandle = <0x1d>;
				pins = "PG8", "PG9";
			};

			uart2_pg_pins: uart2-pg-pins {
				function = "uart2";
				phandle = <0x60>;
				pins = "PG15", "PG16";
			};

			uart2_pg_rts_cts_pins: uart2-pg-rts-cts-pins {
				function = "uart2";
				phandle = <0x61>;
				pins = "PG17", "PG18";
			};

			uart2_ph_pins: uart2-ph-pins {
				function = "uart2";
				phandle = <0x62>;
				pins = "PH5", "PH6";
			};

			uart2_ph_rts_cts_pins: uart2-ph-rts-cts-pins {
				function = "uart2";
				phandle = <0x63>;
				pins = "PH7", "PH8";
			};

			uart2_pi_pins: uart2-pi-pins {
				function = "uart2";
				phandle = <0x5f>;
				pins = "PI5", "PI6";
			};

			uart3_pi_pins: uart3-pi-pins {
				function = "uart3";
				phandle = <0x64>;
				pins = "PI9", "PI10";
			};

			uart4_pi_pins: uart4-pi-pins {
				function = "uart4";
				phandle = <0x65>;
				pins = "PI13", "PI14";
			};

			uart4_pi_rts_cts_pins: uart4-pi-rts-cts-pins {
				function = "uart4";
				phandle = <0x66>;
				pins = "PI15", "PI16";
			};

			uart5_pins: uart5-pins {
				function = "uart5";
				phandle = <0x67>;
				pins = "PH2", "PH3";
			};

			x32clk_fanout_pin: x32clk-fanout-pin {
				function = "clock";
				phandle = <0x68>;
				pins = "PG10";
			};
		};

		r_pio: pinctrl@7022000 {
			#gpio-cells = <0x03>;
			clock-names = "apb", "hosc", "losc";
			clocks = <0x36 0x02 0x12 0x10 0x00>;
			compatible = "allwinner,sun50i-h616-r-pinctrl";
			gpio-controller;
			phandle = <0x1e>;
			reg = <0x7022000 0x400>;

			r_i2c_pins: r-i2c-pins {
				function = "s_i2c";
				phandle = <0x38>;
				pins = "PL0", "PL1";
			};

			r_rsb_pins: r-rsb-pins {
				function = "s_rsb";
				phandle = <0x3a>;
				pins = "PL0", "PL1";
			};
		};

		prcm_ppu: power-controller@7010250 {
			#power-domain-cells = <0x01>;
			compatible = "allwinner,sun50i-h616-prcm-ppu";
			phandle = <0x0e>;
			reg = <0x7010250 0x10>;
		};

		pwm@300a000 {
			#clock-cells = <0x01>;
			#pwm-cells = <0x03>;
			clock-names = "mod", "bus";
			clocks = <0x12 0x02 0x2f>;
			compatible = "allwinner,sun50i-h616-pwm";
			phandle = <0xa9>;
			pinctrl-0 = <0x59>;
			pinctrl-names = "default";
			pwm-base = <0x00>;
			pwm-number = <0x06>;
			reg = <0x300a000 0x400>;
			resets = <0x02 0x0a>;
			status = "okay";
		};

		r_rsb: rsb@7083000 {
			#address-cells = <0x01>;
			#size-cells = <0x00>;
			clock-frequency = <0x2dc6c0>;
			clocks = <0x36 0x0d>;
			compatible = "allwinner,sun50i-h616-rsb", "allwinner,sun8i-a23-rsb";
			interrupts = <0x00 0x6d 0x04>;
			phandle = <0xa0>;
			pinctrl-0 = <0x3a>;
			pinctrl-names = "default";
			reg = <0x7083000 0x400>;
			resets = <0x36 0x07>;
			status = "disabled";
		};

		rtc: rtc@7000000 {
			#clock-cells = <0x01>;
			clock-names = "bus", "hosc", "pll-32k";
			clocks = <0x36 0x0e 0x12 0x02 0x80>;
			compatible = "allwinner,sun50i-h616-rtc";
			interrupts = <0x00 0x68 0x04>;
			phandle = <0x10>;
			reg = <0x7000000 0x400>;
		};

		uart0: serial@5000000 {
			clocks = <0x02 0x42>;
			compatible = "snps,dw-apb-uart";
			dma-names = "tx", "rx";
			dmas = <0x1a 0x0e 0x1a 0x0e>;
			interrupts = <0x00 0x00 0x04>;
			phandle = <0x6e>;
			pinctrl-0 = <0x1b>;
			pinctrl-names = "default";
			reg = <0x5000000 0x400>;
			reg-io-width = <0x04>;
			reg-shift = <0x02>;
			resets = <0x02 0x11>;
			status = "okay";
		};

		uart1: serial@5000400 {
			clocks = <0x02 0x43>;
			compatible = "snps,dw-apb-uart";
			dma-names = "tx", "rx";
			dmas = <0x1a 0x0f 0x1a 0x0f>;
			interrupts = <0x00 0x01 0x04>;
			phandle = <0x6f>;
			pinctrl-0 = <0x1c 0x1d>;
			pinctrl-names = "default";
			reg = <0x5000400 0x400>;
			reg-io-width = <0x04>;
			reg-shift = <0x02>;
			resets = <0x02 0x12>;
			status = "okay";
			uart-has-rtscts;

			bluetooth {
				clock-names = "lpo";
				clocks = <0x10 0x01>;
				compatible = "brcm,bcm43438-bt";
				device-wakeup-gpios = <0x1e 0x00 0x06 0x00>;
				host-wakeup-gpios = <0x1e 0x00 0x05 0x00>;
				shutdown-gpios = <0x1e 0x00 0x04 0x00>;
				vbat-supply = <0x14>;
				vddio-supply = <0x14>;
			};
		};

		uart2: serial@5000800 {
			clocks = <0x02 0x44>;
			compatible = "snps,dw-apb-uart";
			dma-names = "tx", "rx";
			dmas = <0x1a 0x10 0x1a 0x10>;
			interrupts = <0x00 0x02 0x04>;
			phandle = <0x70>;
			reg = <0x5000800 0x400>;
			reg-io-width = <0x04>;
			reg-shift = <0x02>;
			resets = <0x02 0x13>;
			status = "disabled";
		};

		uart3: serial@5000c00 {
			clocks = <0x02 0x45>;
			compatible = "snps,dw-apb-uart";
			dma-names = "tx", "rx";
			dmas = <0x1a 0x11 0x1a 0x11>;
			interrupts = <0x00 0x03 0x04>;
			phandle = <0x71>;
			reg = <0x5000c00 0x400>;
			reg-io-width = <0x04>;
			reg-shift = <0x02>;
			resets = <0x02 0x14>;
			status = "disabled";
		};

		uart4: serial@5001000 {
			clocks = <0x02 0x46>;
			compatible = "snps,dw-apb-uart";
			dma-names = "tx", "rx";
			dmas = <0x1a 0x12 0x1a 0x12>;
			interrupts = <0x00 0x04 0x04>;
			phandle = <0x72>;
			reg = <0x5001000 0x400>;
			reg-io-width = <0x04>;
			reg-shift = <0x02>;
			resets = <0x02 0x15>;
			status = "disabled";
		};

		uart5: serial@5001400 {
			clocks = <0x02 0x47>;
			compatible = "snps,dw-apb-uart";
			dma-names = "tx", "rx";
			dmas = <0x1a 0x13 0x1a 0x13>;
			interrupts = <0x00 0x05 0x04>;
			phandle = <0x73>;
			reg = <0x5001400 0x400>;
			reg-io-width = <0x04>;
			reg-shift = <0x02>;
			resets = <0x02 0x16>;
			status = "disabled";
		};

		spdif: spdif@5093000 {
			#sound-dai-cells = <0x00>;
			clock-names = "apb", "spdif";
			clocks = <0x02 0x58 0x02 0x57>;
			compatible = "allwinner,sun50i-h616-spdif";
			dma-names = "tx";
			dmas = <0x1a 0x02>;
			interrupts = <0x00 0x15 0x04>;
			phandle = <0x7f>;
			pinctrl-0 = <0x24>;
			pinctrl-names = "default";
			reg = <0x5093000 0x400>;
			resets = <0x02 0x22>;
			status = "disabled";
		};

		spi0: spi@5010000 {
			#address-cells = <0x01>;
			#size-cells = <0x00>;
			clock-names = "ahb", "mod";
			clocks = <0x02 0x4f 0x02 0x4d>;
			compatible = "allwinner,sun50i-h616-spi", "allwinner,sun8i-h3-spi";
			dma-names = "rx", "tx";
			dmas = <0x1a 0x16 0x1a 0x16>;
			interrupts = <0x00 0x0c 0x04>;
			phandle = <0x79>;
			reg = <0x5010000 0x1000>;
			resets = <0x02 0x1c>;
			status = "disabled";
		};

		spi1: spi@5011000 {
			#address-cells = <0x01>;
			#size-cells = <0x00>;
			clock-names = "ahb", "mod";
			clocks = <0x02 0x50 0x02 0x4e>;
			compatible = "allwinner,sun50i-h616-spi", "allwinner,sun8i-h3-spi";
			dma-names = "rx", "tx";
			dmas = <0x1a 0x17 0x1a 0x17>;
			interrupts = <0x00 0x0d 0x04>;
			phandle = <0x7a>;
			reg = <0x5011000 0x1000>;
			resets = <0x02 0x1d>;
			status = "disabled";
		};

		sunxi-info {
			compatible = "allwinner,sun50i-h616-sys-info";
			status = "okay";
		};

		syscon: syscon@3000000 {
			#address-cells = <0x01>;
			#size-cells = <0x01>;
			compatible = "allwinner,sun50i-h616-system-control";
			phandle = <0x20>;
			ranges;
			reg = <0x3000000 0x30 0x3000038 0xfc8>;

			sram_a2: sram@100000 {
				#address-cells = <0x01>;
				#size-cells = <0x01>;
				compatible = "mmio-sram";
				phandle = <0x42>;
				ranges = <0x00 0x100000 0x18000>;
				reg = <0x100000 0x18000>;

				scpi_sram: scpi-sram@17c00 {
					compatible = "arm,scp-shmem";
					phandle = <0x43>;
					reg = <0x17c00 0x200>;
				};
			};

			sram_c1: sram@1a00000 {
				#address-cells = <0x01>;
				#size-cells = <0x01>;
				compatible = "mmio-sram";
				phandle = <0x45>;
				ranges = <0x00 0x1a00000 0x200000>;
				reg = <0x1a00000 0x200000>;

				ve_sram: sram-section@0 {
					compatible = "allwinner,sun50i-h616-sram-c1";
					phandle = <0x11>;
					reg = <0x00 0x200000>;
				};
			};

			sram_c: sram@28000 {
				#address-cells = <0x01>;
				#size-cells = <0x01>;
				compatible = "mmio-sram";
				phandle = <0x44>;
				ranges = <0x00 0x28000 0x30000>;
				reg = <0x28000 0x30000>;

				de3_sram: sram-section@0 {
					compatible = "allwinner,sun50i-h616-sram-c", "allwinner,sun50i-a64-sram-c";
					phandle = <0x0b>;
					reg = <0x00 0x1e000>;
				};
			};
		};

		tcon_top: tcon-top@6510000 {
			#clock-cells = <0x01>;
			clock-names = "bus", "tcon-tv0";
			clock-output-names = "tcon-top-tv0";
			clocks = <0x02 0x76 0x02 0x77>;
			compatible = "allwinner,sun50i-h6-tcon-top";
			phandle = <0x33>;
			reg = <0x6510000 0x1000>;
			resets = <0x02 0x35>;

			ports {
				#address-cells = <0x01>;
				#size-cells = <0x00>;

				tcon_top_mixer0_in: port@0 {
					#address-cells = <0x01>;
					#size-cells = <0x00>;
					phandle = <0x94>;
					reg = <0x00>;

					tcon_top_mixer0_in_mixer0: endpoint@0 {
						phandle = <0x0d>;
						reg = <0x00>;
						remote-endpoint = <0x2f>;
					};
				};

				tcon_top_mixer0_out: port@1 {
					#address-cells = <0x01>;
					#size-cells = <0x00>;
					phandle = <0x95>;
					reg = <0x01>;

					tcon_top_mixer0_out_tcon_tv: endpoint@2 {
						phandle = <0x34>;
						reg = <0x02>;
						remote-endpoint = <0x30>;
					};
				};

				tcon_top_hdmi_in: port@4 {
					#address-cells = <0x01>;
					#size-cells = <0x00>;
					phandle = <0x96>;
					reg = <0x04>;

					tcon_top_hdmi_in_tcon_tv: endpoint@0 {
						phandle = <0x35>;
						reg = <0x00>;
						remote-endpoint = <0x31>;
					};
				};

				tcon_top_hdmi_out: port@5 {
					phandle = <0x97>;
					reg = <0x05>;

					tcon_top_hdmi_out_hdmi: endpoint {
						phandle = <0x2d>;
						remote-endpoint = <0x32>;
					};
				};
			};
		};

		ths: thermal-sensor@5070400 {
			#thermal-sensor-cells = <0x01>;
			allwinner,sram = <0x20>;
			clock-names = "bus";
			clocks = <0x02 0x56>;
			compatible = "allwinner,sun50i-h616-ths";
			interrupts = <0x00 0x13 0x04>;
			nvmem-cell-names = "calibration";
			nvmem-cells = <0x25>;
			phandle = <0x3b>;
			reg = <0x5070400 0x400>;
			resets = <0x02 0x21>;
		};

		usbotg: usb@5100000 {
			clocks = <0x02 0x70>;
			compatible = "allwinner,sun50i-h616-musb", "allwinner,sun8i-h3-musb";
			dr_mode = "peripheral";
			extcon = <0x2a 0x00>;
			interrupt-names = "mc";
			interrupts = <0x00 0x19 0x04>;
			phandle = <0x89>;
			phy-names = "usb";
			phys = <0x2a 0x00>;
			reg = <0x5100000 0x400>;
			resets = <0x02 0x32>;
			status = "okay";
		};

		ehci0: usb@5101000 {
			clocks = <0x02 0x68 0x02 0x6c 0x02 0x60>;
			compatible = "allwinner,sun50i-h616-ehci", "generic-ehci";
			interrupts = <0x00 0x1a 0x04>;
			phandle = <0x8a>;
			phy-names = "usb";
			phys = <0x2a 0x00>;
			reg = <0x5101000 0x100>;
			resets = <0x02 0x2a 0x02 0x2e>;
			status = "okay";
		};

		ohci0: usb@5101400 {
			clocks = <0x02 0x68 0x02 0x60>;
			compatible = "allwinner,sun50i-h616-ohci", "generic-ohci";
			interrupts = <0x00 0x1b 0x04>;
			phandle = <0x8b>;
			phy-names = "usb";
			phys = <0x2a 0x00>;
			reg = <0x5101400 0x100>;
			resets = <0x02 0x2a>;
			status = "okay";
		};

		ehci1: usb@5200000 {
			clocks = <0x02 0x69 0x02 0x6d 0x02 0x62>;
			compatible = "allwinner,sun50i-h616-ehci", "generic-ehci";
			interrupts = <0x00 0x1c 0x04>;
			phandle = <0x8c>;
			phy-names = "usb";
			phys = <0x2a 0x01>;
			reg = <0x5200000 0x100>;
			resets = <0x02 0x2b 0x02 0x2f>;
			status = "okay";
		};

		ohci1: usb@5200400 {
			clocks = <0x02 0x69 0x02 0x62>;
			compatible = "allwinner,sun50i-h616-ohci", "generic-ohci";
			interrupts = <0x00 0x1d 0x04>;
			phandle = <0x8d>;
			phy-names = "usb";
			phys = <0x2a 0x01>;
			reg = <0x5200400 0x100>;
			resets = <0x02 0x2b>;
			status = "okay";
		};

		ehci2: usb@5310000 {
			clocks = <0x02 0x6a 0x02 0x6e 0x02 0x64>;
			compatible = "allwinner,sun50i-h616-ehci", "generic-ehci";
			interrupts = <0x00 0x1e 0x04>;
			phandle = <0x8e>;
			phy-names = "usb";
			phys = <0x2a 0x02>;
			reg = <0x5310000 0x100>;
			resets = <0x02 0x2c 0x02 0x30>;
			status = "okay";
		};

		ohci2: usb@5310400 {
			clocks = <0x02 0x6a 0x02 0x64>;
			compatible = "allwinner,sun50i-h616-ohci", "generic-ohci";
			interrupts = <0x00 0x1f 0x04>;
			phandle = <0x8f>;
			phy-names = "usb";
			phys = <0x2a 0x02>;
			reg = <0x5310400 0x100>;
			resets = <0x02 0x2c>;
			status = "okay";
		};

		ehci3: usb@5311000 {
			clocks = <0x02 0x6b 0x02 0x6f 0x02 0x66>;
			compatible = "allwinner,sun50i-h616-ehci", "generic-ehci";
			interrupts = <0x00 0x20 0x04>;
			phandle = <0x90>;
			phy-names = "usb";
			phys = <0x2a 0x03>;
			reg = <0x5311000 0x100>;
			resets = <0x02 0x2d 0x02 0x31>;
			status = "okay";
		};

		ohci3: usb@5311400 {
			clocks = <0x02 0x6b 0x02 0x66>;
			compatible = "allwinner,sun50i-h616-ohci", "generic-ohci";
			interrupts = <0x00 0x21 0x04>;
			phandle = <0x91>;
			phy-names = "usb";
			phys = <0x2a 0x03>;
			reg = <0x5311400 0x100>;
			resets = <0x02 0x2d>;
			status = "okay";
		};

		video-codec@1c0e000 {
			allwinner,sram = <0x11 0x01>;
			clock-names = "ahb", "mod", "ram";
			clocks = <0x02 0x29 0x02 0x28 0x02 0x33>;
			compatible = "allwinner,sun50i-h616-video-engine";
			interrupts = <0x00 0x5d 0x04>;
			reg = <0x1c0e000 0x2000>;
			resets = <0x02 0x05>;
		};

		watchdog: watchdog@30090a0 {
			clocks = <0x12>;
			compatible = "allwinner,sun50i-h616-wdt", "allwinner,sun6i-a31-wdt";
			interrupts = <0x00 0x32 0x04>;
			phandle = <0x47>;
			reg = <0x30090a0 0x20>;
		};
	};

	thermal-zones {

		cpu-thermal {
			polling-delay = <0x3e8>;
			polling-delay-passive = <0x1f4>;
			sustainable-power = <0x3e8>;
			thermal-sensors = <0x3b 0x02>;

			trips {

				cpu_threshold: cpu-trip-0 {
					hysteresis = <0x00>;
					phandle = <0xa3>;
					temperature = <0xea60>;
					type = "passive";
				};

				cpu_target: cpu-trip-1 {
					hysteresis = <0x00>;
					phandle = <0xa4>;
					temperature = <0x11170>;
					type = "passive";
				};

				cpu_critical: cpu-trip-2 {
					hysteresis = <0x00>;
					phandle = <0xa5>;
					temperature = <0x1adb0>;
					type = "critical";
				};
			};
		};

		ddr-thermal {
			polling-delay = <0x00>;
			polling-delay-passive = <0x00>;
			thermal-sensors = <0x3b 0x03>;

			trips {

				ddr_temp_critical: ddr-trip-0 {
					hysteresis = <0x00>;
					phandle = <0xa8>;
					temperature = <0x1adb0>;
					type = "critical";
				};
			};
		};

		gpu-thermal {
			polling-delay = <0x3e8>;
			polling-delay-passive = <0x1f4>;
			sustainable-power = <0x44c>;
			thermal-sensors = <0x3b 0x00>;

			trips {

				gpu_temp_critical: gpu-trip-0 {
					hysteresis = <0x00>;
					phandle = <0xa6>;
					temperature = <0x1adb0>;
					type = "critical";
				};
			};
		};

		ve-thermal {
			polling-delay = <0x00>;
			polling-delay-passive = <0x00>;
			thermal-sensors = <0x3b 0x01>;

			trips {

				ve_temp_critical: ve-trip-0 {
					hysteresis = <0x00>;
					phandle = <0xa7>;
					temperature = <0x1adb0>;
					type = "critical";
				};
			};
		};
	};

	timer {
		arm,no-tick-in-suspend;
		compatible = "arm,armv8-timer";
		interrupts = <0x01 0x0d 0xf04 0x01 0x0e 0xf04 0x01 0x0b 0xf04 0x01 0x0a 0xf04>;
	};

	reg_usb1_vbus: usb1-vbus {
		compatible = "regulator-fixed";
		enable-active-high;
		phandle = <0x2b>;
		regulator-max-microvolt = <0x4c4b40>;
		regulator-min-microvolt = <0x4c4b40>;
		regulator-name = "usb1-vbus";
		status = "okay";
		vin-supply = <0x39>;
	};

	reg_vcc5v: vcc5v {
		compatible = "regulator-fixed";
		phandle = <0x39>;
		regulator-always-on;
		regulator-max-microvolt = <0x4c4b40>;
		regulator-min-microvolt = <0x4c4b40>;
		regulator-name = "vcc-5v";
	};

	wifi_pwrseq: wifi-pwrseq {
		clock-names = "osc32k-out";
		clocks = <0x10 0x01>;
		compatible = "mmc-pwrseq-simple";
		phandle = <0x17>;
		post-power-on-delay-ms = <0xc8>;
		reset-gpios = <0x18 0x06 0x12 0x01>;
	};
};
